# liliumSOC1_sysctrl register map
Vendor: Nordic Semiconductor; Series: liliumSOC1; File version: 1
Registers are 32-bit, read-write, reset 0x0 unless marked. A register's access mark holds for its fields unless they carry their own. Offsets are from the block's base; [hi:lo] are bit positions; lines under a group give offsets from that group; 'fields as' and 'values as' point back to an identical list.

## VDETAO5V0_S — VDETAO5V0 peripheral
Base 0x5F975000
0x00 TASKS_PWRUP wo — Power up voltage detector
  [0] TASKS_PWRUP
    1=Trigger task
0x04 TASKS_PWRDOWN wo — Power down voltage detector
  [0] TASKS_PWRDOWN
    1=Trigger task
0x100 EVENTS_READY — Power up done
  [0] EVENTS_READY
    0=NotGenerated (Event not generated); 1=Generated (Event generated)
0x104 EVENTS_SETTLED — Settled flag for MODE handshake
  [0] EVENTS_SETTLED
    values as EVENTS_READY.EVENTS_READY
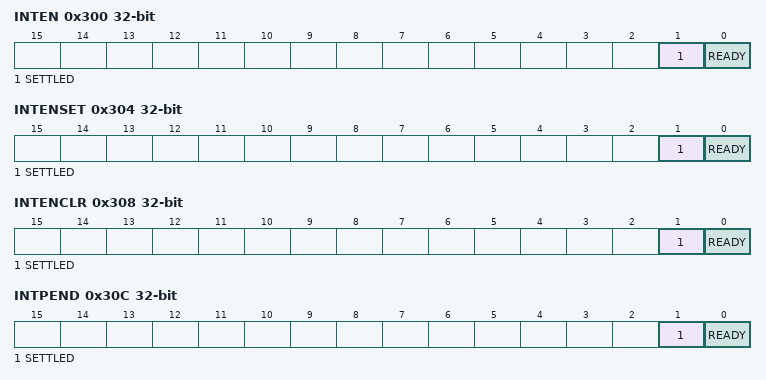
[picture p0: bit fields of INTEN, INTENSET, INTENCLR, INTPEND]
0x300 INTEN — Enable or disable interrupt
  [1] SETTLED — Enable or disable interrupt for event SETTLED
    0=Disabled; 1=Enabled
  [0] READY — Enable or disable interrupt for event READY
    0=Disabled; 1=Enabled
0x304 INTENSET — Enable interrupt
  [1] SETTLED — Write '1' to enable interrupt for event SETTLED
    on read: 0=Disabled (Read: Disabled); 1=Enabled (Read: Enabled) | on write: 1=Set (Enable)
  [0] READY — Write '1' to enable interrupt for event READY
    values as SETTLED
0x308 INTENCLR — Disable interrupt
  [1] SETTLED — Write '1' to disable interrupt for event SETTLED
    on read: 0=Disabled (Read: Disabled); 1=Enabled (Read: Enabled) | on write: 1=Clear (Disable)
  [0] READY — Write '1' to disable interrupt for event READY
    values as SETTLED
0x30C INTPEND ro — Pending interrupts
  [1] SETTLED — Read pending status of interrupt for event SETTLED
    on read: 0=NotPending (Read: Not pending); 1=Pending (Read: Pending)
  [0] READY — Read pending status of interrupt for event READY
    values as SETTLED
0x400 STATUS ro — Voltage detector status
  [1:0] MODE — Current voltage detector mode
    0=High power mode; 1=Low power mode; 2=Ultra-low power refresh mode
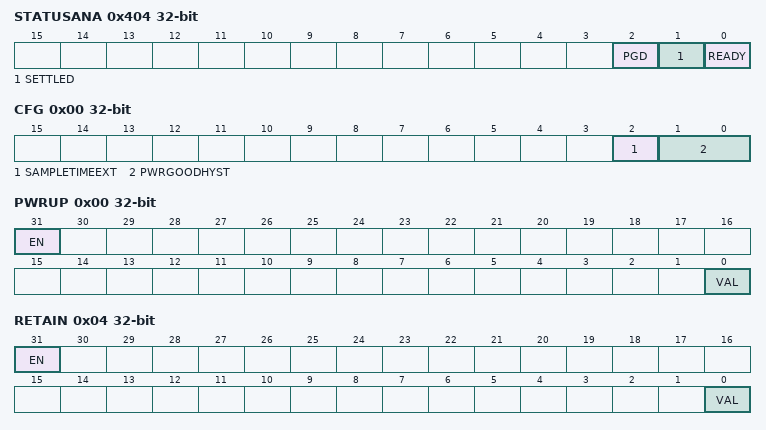
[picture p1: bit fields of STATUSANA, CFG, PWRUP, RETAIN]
0x404 STATUSANA ro — Status of analog module output signals
  [2] PGD — Current value of the PGD signal from the analog module
  [1] SETTLED — Current value of the SETTLED signal from the analog module
  [0] READY — Current value of the READY signal from the analog module
0x410 CONFIG group — Unspecified
  0x00 CFG — Voltage detector configuration
    [2] SAMPLETIMEEXT — Extend VDD sense sample time
      0=Disabled (Sample time extention disabled); 1=Enabled (Sample time 200ns extention enabled)
    [1:0] PWRGOODHYST — Power good detector hysteresis voltage value
      0=Val0V050 (Hysteresis voltage is 50mV); 1=Val0V025 (Hysteresis voltage is 25mV); 2=Val0V150 (Hysteresis voltage is 150mV); 3=Val0V100 (Hysteresis voltage is 100mV)
  0x04 PWRGOODLVL reset 0x6 — Power good detector threshold voltage level
    [2:0] VAL — Threshold voltage value.
0x440 TRIM group — Unspecified
  0x00 PWRGOOD — Power good detector trimming
    [2:0] VAL — Threshold voltage trimming value
0x480 MIRROR reset 0x1 — Enable LOCK for mirrored registers
  [0] LOCK — Lock for mirrored registers
    0=Disabled (Lock disabled); 1=Enabled (Lock enabled)
0x484 MODE — Voltage detector mode
  [1:0] MODE
    0=Automatically handled by the peripheral; 1=High power mode; 2=Low power mode; 3=Ultra-low power refresh mode
0x500 OVERRIDE group — Unspecified
  0x00 PWRUP — Override the PWRUP signal to the analog module
    [31] EN — Enable the override
      0=Disabled (Override is disabled); 1=Enabled (Override is enabled)
    [0] VAL — Override value for the signal
  0x04 RETAIN — Override the RETAIN signal to the analog module
    fields as OVERRIDE.PWRUP
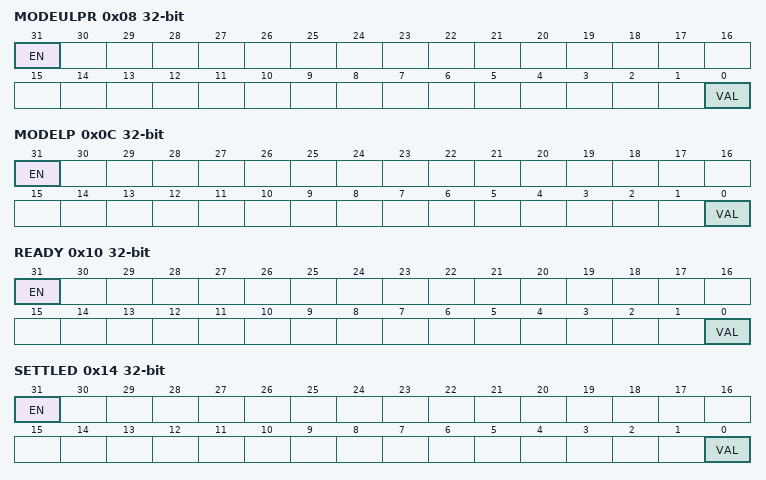
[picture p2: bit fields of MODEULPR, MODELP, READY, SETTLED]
  0x08 MODEULPR — Override the MODE_ULPR signal to the analog module
    fields as OVERRIDE.PWRUP
  0x0C MODELP — Override the MODE_LP signal to the analog module
    fields as OVERRIDE.PWRUP
  0x10 READY — Override the READY signal from the analog module
    [31] EN — Enable the override
      values as OVERRIDE.PWRUP.EN
    [0] VAL — Current value of the signal
  0x14 SETTLED — Override the SETTLED signal from the analog module
    fields as OVERRIDE.READY
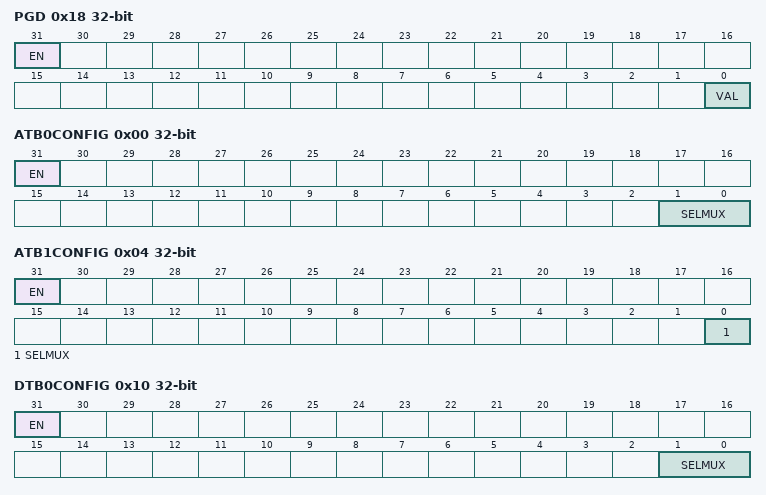
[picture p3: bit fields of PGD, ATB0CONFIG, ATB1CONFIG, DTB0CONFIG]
  0x18 PGD — Override the PGD signal from the analog module
    fields as OVERRIDE.READY
0x600 DFT group — Unspecified
  0x00 ATB0CONFIG — Analog Test Bus 0 (ATB0) configuration
    [31] EN — Enable the analog test bus
      0=Disabled (Analog test bus is disabled); 1=Enabled (Analog test bus is enabled)
    [1:0] SELMUX — Select multiplexer for ATB0
      0=None selected; 1=Connect IDBG_1U to ATB0; 2=ConnectVrefVfbUnbuf (Connect input of VREF/VFB_DIV buffer to ATB0); 3=Connect VSS to ATB0
  0x04 ATB1CONFIG — Analog Test Bus 1 (ATB1) configuration
    [31] EN — Enable the analog test bus
      values as DFT.ATB0CONFIG.EN
    [0] SELMUX — Select multiplexer for ATB1
      0=ConnectVrefBuf (Connect buffered VREF to ATB1); 1=ConnectVfbBuf (Connect buffered VFB_DIV to ATB1)
  0x10 DTB0CONFIG — Digital Test Bus 0 (DTB0) configuration
    [31] EN — Enable the digital test bus
      0=Disabled (Digital test bus is disabled); 1=Enabled (Digital test bus is enabled)
    [1:0] SELMUX — Select multiplexer for DTB0
      0=PgdCompReady (VDETAO5V0_PGD_COMP_READY); 1=PgdUnlatched (Unlatched PGD signal); 2=MODE_LP_PGD; 3=MODE_ULPR_PGD
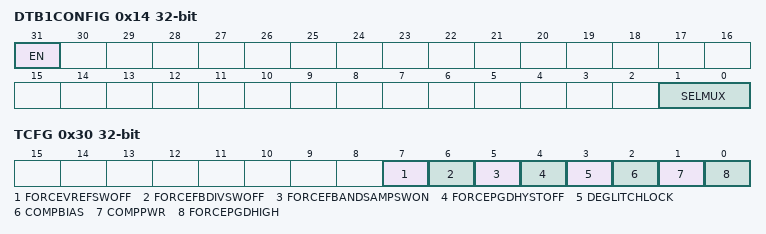
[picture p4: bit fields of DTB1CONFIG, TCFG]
  0x14 DTB1CONFIG — Digital Test Bus 1 (DTB1) configuration
    [31] EN — Enable the digital test bus
      values as DFT.DTB0CONFIG.EN
    [1:0] SELMUX — Select multiplexer for DTB1
      0=Pgd (VDETAO5V0_PGD); 1=PWRUP_PGD; 2=SETTLED_VDETAO5V0; 3=READY_VDETAO5V0
  0x1C DTB3CONFIG — Digital Test Bus 3 (DTB3) configuration
    [27] PWRUPDELTEST — Enable the PWRUP delay test circuit
      0=Disabled (PWRUP delay test circuit is disabled); 1=Enabled (PWRUP delay test circuit is enabled)
  0x30 TCFG — Test mode configuration
    [7] FORCEVREFSWOFF — Force vref sample switch off for voltage force
      0=Disabled (Normal operation); 1=Enabled (Force enabled)
    [6] FORCEFBDIVSWOFF — Force fb div sample switch off for voltage force
      0=Disabled (Normal operation); 1=Enabled (Force enabled)
    [5] FORCEFBANDSAMPSWON — Force fb div on and sampling switch on
      0=Disabled (Normal operation); 1=Enabled (Force enabled)
    [4] FORCEPGDHYSTOFF — Force PGD hysteresis off
      0=Disabled (Normal operation); 1=Enabled (Force enabled)
    [3] DEGLITCHLOCK — Control lock of PGD deglitch logic
      0=Unlocked (Deglitch logic unlocked); 1=Locked (Deglitch logic locked)
    [2] COMPBIAS — Control PGD comparator 1uA bias ON/OFF
      0=Off (Comparator bias forced off); 1=On (Comparator bias forced on)
    [1] COMPPWR — Control PGD comparator ON/OFF
      0=Off (Comparator forced off); 1=On (Comparator forced on)
    [0] FORCEPGDHIGH — Force VDETAO5V0_PGD_AO_0V8 high
      0=Disabled (Normal operation); 1=Enabled (Force enabled)
